VERSION "1.0"

NS_ :

BS_:

BU_: ECU1 ECU2 Dashboard

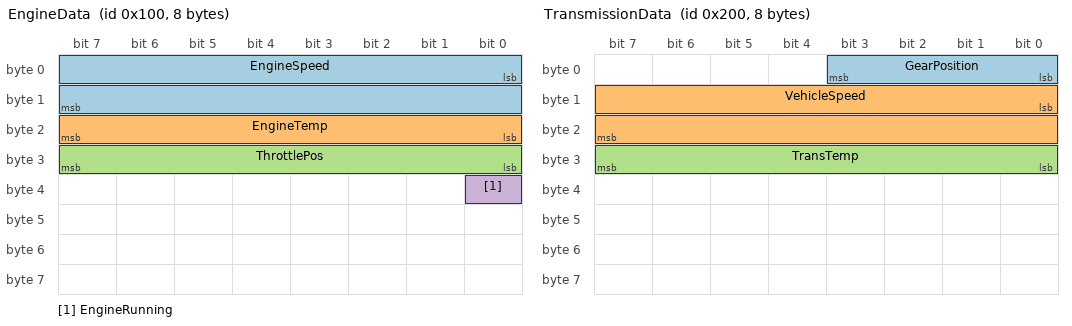
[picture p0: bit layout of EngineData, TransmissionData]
BO_ 256 EngineData: 8 ECU1
 SG_ EngineSpeed : 0|16@1+ (0.25,0) [0|16383.75] "rpm" Dashboard
 SG_ EngineTemp : 16|8@1+ (1,-40) [-40|215] "degC" Dashboard
 SG_ ThrottlePos : 24|8@1+ (0.392157,0) [0|100] "%" Dashboard
 SG_ EngineRunning : 32|1@1+ (1,0) [0|1] "" Dashboard

BO_ 512 TransmissionData: 8 ECU1
 SG_ GearPosition : 0|4@1+ (1,0) [0|8] "" Dashboard
 SG_ VehicleSpeed : 8|16@1+ (0.01,0) [0|655.35] "km/h" Dashboard
 SG_ TransTemp : 24|8@1+ (1,-40) [-40|215] "degC" ECU2

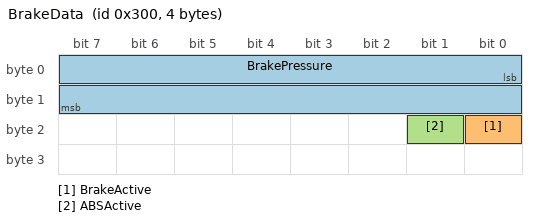
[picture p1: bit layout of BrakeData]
BO_ 768 BrakeData: 4 ECU2
 SG_ BrakePressure : 0|16@1+ (0.1,0) [0|6553.5] "bar" Dashboard
 SG_ BrakeActive : 16|1@1+ (1,0) [0|1] "" ECU1
 SG_ ABSActive : 17|1@1+ (1,0) [0|1] "" Dashboard

BO_ 1024 SteeringData: 8 ECU2
 SG_ SteeringAngle : 0|16@1- (0.1,0) [-3276.8|3276.7] "deg" Dashboard
 SG_ SteeringSpeed : 16|8@1+ (4,0) [0|1016] "deg/s" ECU1

CM_ BO_ 256 "Engine sensor data from ECU1";
CM_ BO_ 512 "Transmission and vehicle speed data";
CM_ BO_ 768 "Brake system data";
CM_ BO_ 1024 "Steering system data";
CM_ SG_ 256 EngineSpeed "Engine rotational speed in RPM";
CM_ SG_ 256 EngineTemp "Engine coolant temperature";
CM_ SG_ 512 VehicleSpeed "Vehicle speed in km/h";
CM_ SG_ 1024 SteeringAngle "Steering wheel angle - negative is left";
